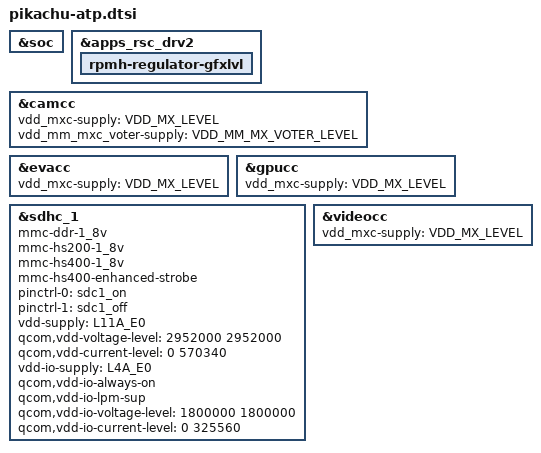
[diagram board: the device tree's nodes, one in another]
// SPDX-License-Identifier: BSD-3-Clause
/*
 * Copyright (c) Qualcomm Technologies, Inc. and/or its subsidiaries.
 */

#include "pikachu-pmic-overlay.dtsi"
#include "pikachu-qpt-overlay.dtsi"
#include "pikachu-thermal-overlay.dtsi"

&soc {
};

&apps_rsc_drv2 {
	rpmh-regulator-gfxlvl {
		status = "okay";
	};
};

&camcc {
	vdd_mxc-supply = <&VDD_MX_LEVEL>;
	vdd_mm_mxc_voter-supply = <&VDD_MM_MX_VOTER_LEVEL>;
};

&evacc {
	vdd_mxc-supply = <&VDD_MX_LEVEL>;
};

&gpucc {
	vdd_mxc-supply = <&VDD_MX_LEVEL>;
};

&sdhc_1 {
	status = "ok";

	mmc-ddr-1_8v;
	mmc-hs200-1_8v;
	mmc-hs400-1_8v;
	mmc-hs400-enhanced-strobe;

	pinctrl-names = "default", "sleep";
	pinctrl-0 = <&sdc1_on>;
	pinctrl-1 = <&sdc1_off>;

	vdd-supply = <&L11A_E0>;
	qcom,vdd-voltage-level = <2952000 2952000>;
	qcom,vdd-current-level = <0 570340>;

	vdd-io-supply = <&L4A_E0>;
	qcom,vdd-io-always-on;
	qcom,vdd-io-lpm-sup;
	qcom,vdd-io-voltage-level = <1800000 1800000>;
	qcom,vdd-io-current-level = <0 325560>;
};

&videocc {
	vdd_mxc-supply = <&VDD_MX_LEVEL>;
};
